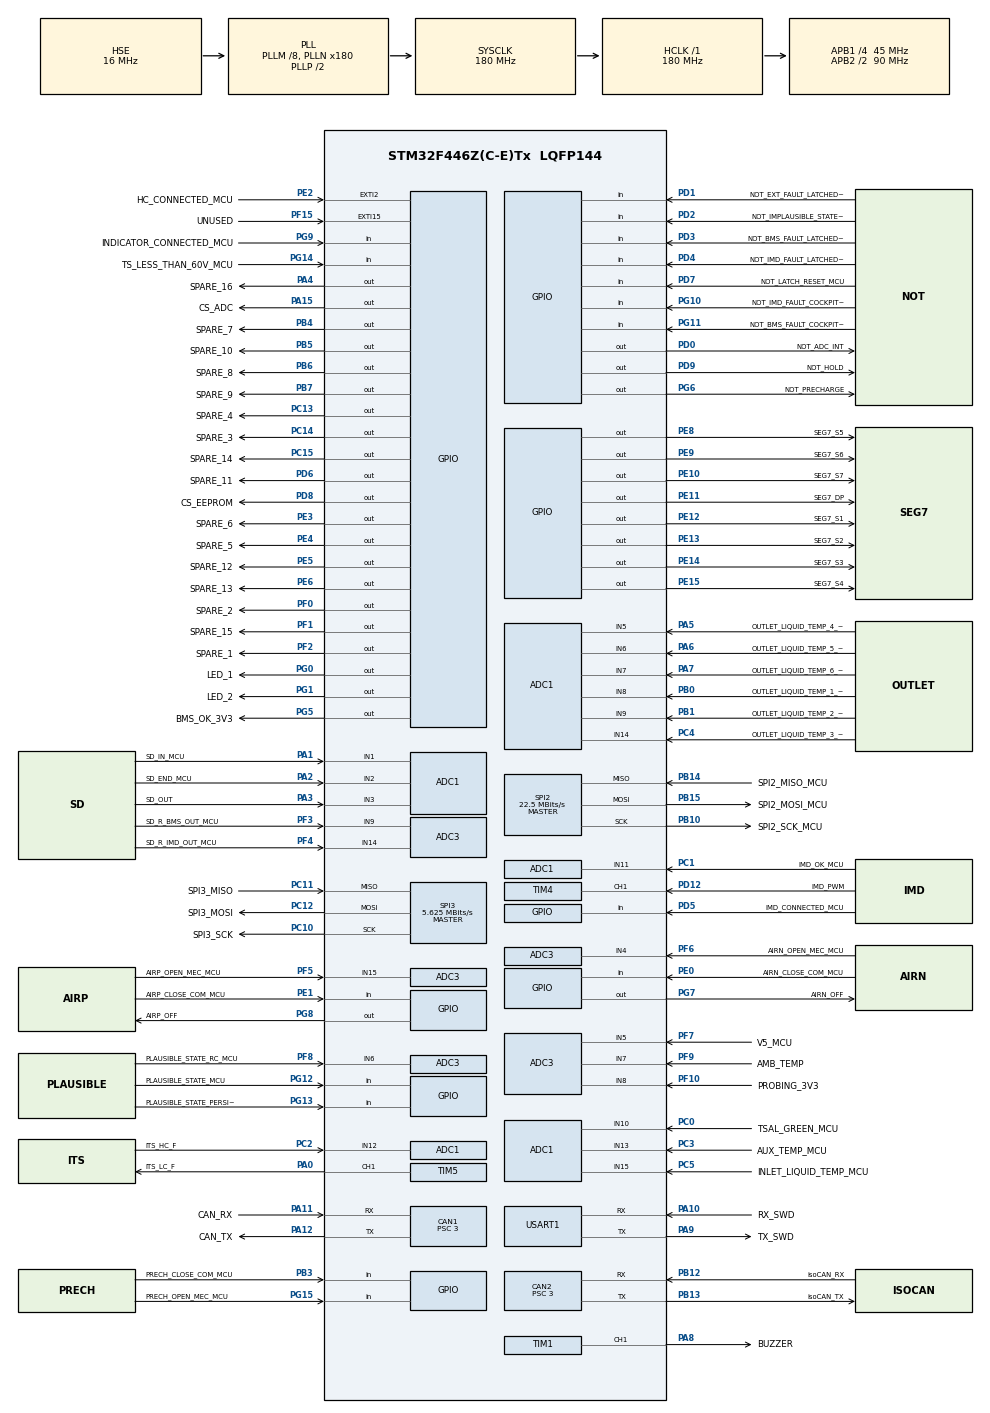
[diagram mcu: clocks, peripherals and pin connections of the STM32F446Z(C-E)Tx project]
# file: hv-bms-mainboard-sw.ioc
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ADC1.Channel-0\#ChannelRegularConversion=ADC_CHANNEL_15
ADC1.Channel-1\#ChannelRegularConversion=ADC_CHANNEL_1
ADC1.Channel-10\#ChannelRegularConversion=ADC_CHANNEL_11
ADC1.Channel-11\#ChannelRegularConversion=ADC_CHANNEL_12
ADC1.Channel-12\#ChannelRegularConversion=ADC_CHANNEL_13
ADC1.Channel-13\#ChannelRegularConversion=ADC_CHANNEL_14
ADC1.Channel-14\#ChannelRegularConversion=ADC_CHANNEL_15
ADC1.Channel-2\#ChannelRegularConversion=ADC_CHANNEL_2
ADC1.Channel-3\#ChannelRegularConversion=ADC_CHANNEL_3
ADC1.Channel-4\#ChannelRegularConversion=ADC_CHANNEL_5
ADC1.Channel-5\#ChannelRegularConversion=ADC_CHANNEL_6
ADC1.Channel-6\#ChannelRegularConversion=ADC_CHANNEL_7
ADC1.Channel-7\#ChannelRegularConversion=ADC_CHANNEL_8
ADC1.Channel-8\#ChannelRegularConversion=ADC_CHANNEL_9
ADC1.Channel-9\#ChannelRegularConversion=ADC_CHANNEL_10
ADC1.ClockPrescaler=ADC_CLOCK_SYNC_PCLK_DIV4
ADC1.DiscontinuousConvMode=DISABLE
ADC1.EOCSelection=ADC_EOC_SEQ_CONV
ADC1.NbrOfConversion=15
ADC1.NbrOfConversionFlag=1
ADC1.Rank-0\#ChannelRegularConversion=1
ADC1.Rank-1\#ChannelRegularConversion=2
ADC1.Rank-10\#ChannelRegularConversion=11
ADC1.Rank-11\#ChannelRegularConversion=12
ADC1.Rank-12\#ChannelRegularConversion=13
ADC1.Rank-13\#ChannelRegularConversion=14
ADC1.Rank-14\#ChannelRegularConversion=15
ADC1.Rank-2\#ChannelRegularConversion=3
ADC1.Rank-3\#ChannelRegularConversion=4
ADC1.Rank-4\#ChannelRegularConversion=5
ADC1.Rank-5\#ChannelRegularConversion=6
ADC1.Rank-6\#ChannelRegularConversion=7
ADC1.Rank-7\#ChannelRegularConversion=8
ADC1.Rank-8\#ChannelRegularConversion=9
ADC1.Rank-9\#ChannelRegularConversion=10
ADC1.SamplingTime-0\#ChannelRegularConversion=ADC_SAMPLETIME_15CYCLES
ADC1.SamplingTime-1\#ChannelRegularConversion=ADC_SAMPLETIME_15CYCLES
ADC1.SamplingTime-10\#ChannelRegularConversion=ADC_SAMPLETIME_15CYCLES
ADC1.SamplingTime-11\#ChannelRegularConversion=ADC_SAMPLETIME_15CYCLES
ADC1.SamplingTime-12\#ChannelRegularConversion=ADC_SAMPLETIME_15CYCLES
ADC1.SamplingTime-13\#ChannelRegularConversion=ADC_SAMPLETIME_15CYCLES
ADC1.SamplingTime-14\#ChannelRegularConversion=ADC_SAMPLETIME_15CYCLES
ADC1.SamplingTime-2\#ChannelRegularConversion=ADC_SAMPLETIME_15CYCLES
ADC1.SamplingTime-3\#ChannelRegularConversion=ADC_SAMPLETIME_15CYCLES
ADC1.SamplingTime-4\#ChannelRegularConversion=ADC_SAMPLETIME_15CYCLES
ADC1.SamplingTime-5\#ChannelRegularConversion=ADC_SAMPLETIME_15CYCLES
ADC1.SamplingTime-6\#ChannelRegularConversion=ADC_SAMPLETIME_15CYCLES
ADC1.SamplingTime-7\#ChannelRegularConversion=ADC_SAMPLETIME_15CYCLES
ADC1.SamplingTime-8\#ChannelRegularConversion=ADC_SAMPLETIME_15CYCLES
ADC1.SamplingTime-9\#ChannelRegularConversion=ADC_SAMPLETIME_15CYCLES
ADC1.master=1
ADC3.Channel-10\#ChannelRegularConversion=ADC_CHANNEL_8
ADC3.Channel-11\#ChannelRegularConversion=ADC_CHANNEL_9
ADC3.Channel-12\#ChannelRegularConversion=ADC_CHANNEL_14
ADC3.Channel-13\#ChannelRegularConversion=ADC_CHANNEL_15
ADC3.Channel-6\#ChannelRegularConversion=ADC_CHANNEL_4
ADC3.Channel-7\#ChannelRegularConversion=ADC_CHANNEL_5
ADC3.Channel-8\#ChannelRegularConversion=ADC_CHANNEL_6
ADC3.Channel-9\#ChannelRegularConversion=ADC_CHANNEL_7
ADC3.EOCSelection=ADC_EOC_SEQ_CONV
ADC3.NbrOfConversion=8
ADC3.NbrOfConversionFlag=1
ADC3.Rank-10\#ChannelRegularConversion=5
ADC3.Rank-11\#ChannelRegularConversion=6
ADC3.Rank-12\#ChannelRegularConversion=7
ADC3.Rank-13\#ChannelRegularConversion=8
ADC3.Rank-6\#ChannelRegularConversion=1
ADC3.Rank-7\#ChannelRegularConversion=2
ADC3.Rank-8\#ChannelRegularConversion=3
ADC3.Rank-9\#ChannelRegularConversion=4
ADC3.SamplingTime-10\#ChannelRegularConversion=ADC_SAMPLETIME_15CYCLES
ADC3.SamplingTime-11\#ChannelRegularConversion=ADC_SAMPLETIME_15CYCLES
ADC3.SamplingTime-12\#ChannelRegularConversion=ADC_SAMPLETIME_15CYCLES
ADC3.SamplingTime-13\#ChannelRegularConversion=ADC_SAMPLETIME_3CYCLES
ADC3.SamplingTime-6\#ChannelRegularConversion=ADC_SAMPLETIME_15CYCLES
ADC3.SamplingTime-7\#ChannelRegularConversion=ADC_SAMPLETIME_15CYCLES
ADC3.SamplingTime-8\#ChannelRegularConversion=ADC_SAMPLETIME_15CYCLES
ADC3.SamplingTime-9\#ChannelRegularConversion=ADC_SAMPLETIME_15CYCLES
ADC3.ScanConvMode=ENABLE
CAN1.ABOM=ENABLE
CAN1.BS1=CAN_BS1_12TQ
CAN1.BS2=CAN_BS2_2TQ
CAN1.CalculateBaudRate=1000000
CAN1.CalculateTimeBit=1000
CAN1.CalculateTimeQuantum=66.66666666666666
CAN1.NART=ENABLE
CAN1.Prescaler=3
CAN2.ABOM=ENABLE
CAN2.BS1=CAN_BS1_12TQ
CAN2.BS2=CAN_BS2_2TQ
CAN2.CalculateBaudRate=1000000
CAN2.CalculateTimeBit=1000
CAN2.CalculateTimeQuantum=66.66666666666666
CAN2.NART=ENABLE
CAN2.Prescaler=3
Dma.ADC1.0.Direction=DMA_PERIPH_TO_MEMORY
Dma.ADC1.0.FIFOMode=DMA_FIFOMODE_DISABLE
Dma.ADC1.0.Instance=DMA2_Stream0
Dma.ADC1.0.MemDataAlignment=DMA_MDATAALIGN_HALFWORD
Dma.ADC1.0.MemInc=DMA_MINC_ENABLE
Dma.ADC1.0.Mode=DMA_NORMAL
Dma.ADC1.0.PeriphDataAlignment=DMA_PDATAALIGN_HALFWORD
Dma.ADC1.0.PeriphInc=DMA_PINC_DISABLE
Dma.ADC1.0.Priority=DMA_PRIORITY_LOW
Dma.ADC3.1.Direction=DMA_PERIPH_TO_MEMORY
Dma.ADC3.1.FIFOMode=DMA_FIFOMODE_DISABLE
Dma.ADC3.1.Instance=DMA2_Stream1
Dma.ADC3.1.MemDataAlignment=DMA_MDATAALIGN_HALFWORD
Dma.ADC3.1.MemInc=DMA_MINC_ENABLE
Dma.ADC3.1.Mode=DMA_NORMAL
Dma.ADC3.1.PeriphDataAlignment=DMA_PDATAALIGN_HALFWORD
Dma.ADC3.1.PeriphInc=DMA_PINC_DISABLE
Dma.ADC3.1.Priority=DMA_PRIORITY_LOW
Dma.Request0=ADC1
Dma.Request1=ADC3
Dma.Request2=USART1_RX
Dma.Request3=USART1_TX
Dma.USART1_RX.2.Direction=DMA_PERIPH_TO_MEMORY
Dma.USART1_RX.2.FIFOMode=DMA_FIFOMODE_DISABLE
Dma.USART1_RX.2.Instance=DMA2_Stream2
Dma.USART1_RX.2.MemDataAlignment=DMA_MDATAALIGN_BYTE
Dma.USART1_RX.2.MemInc=DMA_MINC_ENABLE
Dma.USART1_RX.2.Mode=DMA_CIRCULAR
Dma.USART1_RX.2.PeriphDataAlignment=DMA_PDATAALIGN_BYTE
Dma.USART1_RX.2.PeriphInc=DMA_PINC_DISABLE
Dma.USART1_RX.2.Priority=DMA_PRIORITY_LOW
Dma.USART1_TX.3.Direction=DMA_MEMORY_TO_PERIPH
Dma.USART1_TX.3.FIFOMode=DMA_FIFOMODE_DISABLE
Dma.USART1_TX.3.Instance=DMA2_Stream7
Dma.USART1_TX.3.MemDataAlignment=DMA_MDATAALIGN_BYTE
Dma.USART1_TX.3.MemInc=DMA_MINC_ENABLE
Dma.USART1_TX.3.Mode=DMA_NORMAL
Dma.USART1_TX.3.PeriphDataAlignment=DMA_PDATAALIGN_BYTE
Dma.USART1_TX.3.PeriphInc=DMA_PINC_DISABLE
Dma.USART1_TX.3.Priority=DMA_PRIORITY_LOW
Mcu.Family=STM32F4
Mcu.Name=STM32F446Z(C-E)Tx
Mcu.Package=LQFP144
NVIC.CAN1_RX0_IRQn=true\:0\:0\:false\:false\:true\:true\:true\:true
NVIC.CAN1_RX1_IRQn=true\:0\:0\:false\:false\:true\:true\:true\:true
NVIC.CAN1_SCE_IRQn=true\:0\:0\:false\:false\:true\:true\:true\:true
NVIC.CAN2_RX0_IRQn=true\:0\:0\:false\:false\:true\:true\:true\:true
NVIC.CAN2_RX1_IRQn=true\:0\:0\:false\:false\:true\:true\:true\:true
NVIC.CAN2_SCE_IRQn=true\:0\:0\:false\:false\:true\:true\:true\:true
NVIC.DMA2_Stream0_IRQn=true\:0\:0\:false\:false\:true\:false\:true\:true
NVIC.DMA2_Stream1_IRQn=true\:0\:0\:false\:false\:true\:false\:true\:true
NVIC.DMA2_Stream2_IRQn=true\:0\:0\:false\:false\:true\:false\:true\:true
NVIC.DMA2_Stream7_IRQn=true\:0\:0\:false\:false\:true\:false\:true\:true
NVIC.EXTI2_IRQn=true\:0\:0\:false\:false\:true\:true\:true\:true
NVIC.PriorityGroup=NVIC_PRIORITYGROUP_4
NVIC.TIM4_IRQn=true\:0\:0\:false\:false\:true\:true\:true\:true
NVIC.TIM6_DAC_IRQn=true\:0\:0\:false\:false\:true\:true\:true\:true
NVIC.TIM7_IRQn=true\:0\:0\:false\:false\:true\:true\:true\:true
NVIC.USART1_IRQn=true\:0\:0\:false\:false\:true\:true\:true\:true
PA0-WKUP.GPIO_Label=ITS_LC_F
PA0-WKUP.Signal=S_TIM5_CH1
PA1.GPIO_Label=SD_IN_MCU
PA1.Signal=ADCx_IN1
PA10.GPIO_Label=RX_SWD
PA10.Mode=Asynchronous
PA10.Signal=USART1_RX
PA11.GPIO_Label=CAN_RX
PA11.Mode=CAN_Activate
PA11.Signal=CAN1_RX
PA12.GPIO_Label=CAN_TX
PA12.Mode=CAN_Activate
PA12.Signal=CAN1_TX
PA13.GPIO_Label=SWDIO
PA13.Mode=Serial_Wire
PA13.Signal=SYS_JTMS-SWDIO
PA14.GPIO_Label=SWCLK
PA14.Mode=Serial_Wire
PA14.Signal=SYS_JTCK-SWCLK
PA15.GPIO_Label=CS_ADC
PA15.Signal=GPIO_Output
PA2.GPIO_Label=SD_END_MCU
PA2.Signal=ADCx_IN2
PA3.GPIO_Label=SD_OUT
PA3.Signal=ADCx_IN3
PA4.GPIO_Label=SPARE_16
PA4.Signal=GPIO_Output
PA5.GPIO_Label=OUTLET_LIQUID_TEMP_4_MCU
PA5.Signal=ADCx_IN5
PA6.GPIO_Label=OUTLET_LIQUID_TEMP_5_MCU
PA6.Signal=ADCx_IN6
PA7.GPIO_Label=OUTLET_LIQUID_TEMP_6_MCU
PA7.Signal=ADCx_IN7
PA8.GPIO_Label=BUZZER
PA8.Signal=S_TIM1_CH1
PA9.GPIO_Label=TX_SWD
PA9.Mode=Asynchronous
PA9.Signal=USART1_TX
PB0.GPIO_Label=OUTLET_LIQUID_TEMP_1_MCU
PB0.Signal=ADCx_IN8
PB1.GPIO_Label=OUTLET_LIQUID_TEMP_2_MCU
PB1.Signal=ADCx_IN9
PB10.GPIO_Label=SPI2_SCK_MCU
PB10.Mode=Full_Duplex_Master
PB10.Signal=SPI2_SCK
PB12.GPIO_Label=isoCAN_RX
PB12.Mode=CAN_Activate
PB12.Signal=CAN2_RX
PB13.GPIO_Label=isoCAN_TX
PB13.Mode=CAN_Activate
PB13.Signal=CAN2_TX
PB14.GPIO_Label=SPI2_MISO_MCU
PB14.Mode=Full_Duplex_Master
PB14.Signal=SPI2_MISO
PB15.GPIO_Label=SPI2_MOSI_MCU
PB15.Mode=Full_Duplex_Master
PB15.Signal=SPI2_MOSI
PB3.GPIO_Label=PRECH_CLOSE_COM_MCU
PB3.Signal=GPIO_Input
PB4.GPIO_Label=SPARE_7
PB4.Signal=GPIO_Output
PB5.GPIO_Label=SPARE_10
PB5.Signal=GPIO_Output
PB6.GPIO_Label=SPARE_8
PB6.Signal=GPIO_Output
PB7.GPIO_Label=SPARE_9
PB7.Signal=GPIO_Output
PC0.GPIO_Label=TSAL_GREEN_MCU
PC0.Signal=ADCx_IN10
PC1.GPIO_Label=IMD_OK_MCU
PC1.Signal=ADCx_IN11
PC10.GPIO_Label=SPI3_SCK
PC10.Mode=Full_Duplex_Master
PC10.Signal=SPI3_SCK
PC11.GPIO_Label=SPI3_MISO
PC11.Mode=Full_Duplex_Master
PC11.Signal=SPI3_MISO
PC12.GPIO_Label=SPI3_MOSI
PC12.Mode=Full_Duplex_Master
PC12.Signal=SPI3_MOSI
PC13.GPIO_Label=SPARE_4
PC13.Signal=GPIO_Output
PC14-OSC32_IN.GPIO_Label=SPARE_3
PC14-OSC32_IN.Signal=GPIO_Output
PC15-OSC32_OUT.GPIO_Label=SPARE_14
PC15-OSC32_OUT.Signal=GPIO_Output
PC2.GPIO_Label=ITS_HC_F
PC2.Signal=ADCx_IN12
PC3.GPIO_Label=AUX_TEMP_MCU
PC3.Signal=ADCx_IN13
PC4.GPIO_Label=OUTLET_LIQUID_TEMP_3_MCU
PC4.Signal=ADCx_IN14
PC5.GPIO_Label=INLET_LIQUID_TEMP_MCU
PC5.Signal=ADCx_IN15
PD0.GPIO_Label=NOT_ADC_INT
PD0.Signal=GPIO_Output
PD1.GPIO_Label=NOT_EXT_FAULT_LATCHED_MCU
PD1.Signal=GPIO_Input
PD12.GPIO_Label=IMD_PWM
PD12.Signal=S_TIM4_CH1
PD2.GPIO_Label=NOT_IMPLAUSIBLE_STATE_LATCHED_MCU
PD2.Signal=GPIO_Input
PD3.GPIO_Label=NOT_BMS_FAULT_LATCHED_MCU
PD3.Signal=GPIO_Input
PD4.GPIO_Label=NOT_IMD_FAULT_LATCHED_MCU
PD4.Signal=GPIO_Input
PD5.GPIO_Label=IMD_CONNECTED_MCU
PD5.Signal=GPIO_Input
PD6.GPIO_Label=SPARE_11
PD6.Signal=GPIO_Output
PD7.GPIO_Label=NOT_LATCH_RESET_MCU
PD7.Signal=GPIO_Input
PD8.GPIO_Label=CS_EEPROM
PD8.Signal=GPIO_Output
PD9.GPIO_Label=NOT_HOLD
PD9.Signal=GPIO_Output
PE0.GPIO_Label=AIRN_CLOSE_COM_MCU
PE0.GPIO_PuPd=GPIO_NOPULL
PE0.Signal=GPIO_Input
PE1.GPIO_Label=AIRP_CLOSE_COM_MCU
PE1.Signal=GPIO_Input
PE10.GPIO_Label=SEG7_S7
PE10.Signal=GPIO_Output
PE11.GPIO_Label=SEG7_DP
PE11.Signal=GPIO_Output
PE12.GPIO_Label=SEG7_S1
PE12.Signal=GPIO_Output
PE13.GPIO_Label=SEG7_S2
PE13.Signal=GPIO_Output
PE14.GPIO_Label=SEG7_S3
PE14.Signal=GPIO_Output
PE15.GPIO_Label=SEG7_S4
PE15.Signal=GPIO_Output
PE2.GPIO_Label=HC_CONNECTED_MCU
PE2.GPIO_ModeDefaultEXTI=GPIO_MODE_IT_RISING_FALLING
PE2.Signal=GPXTI2
PE3.GPIO_Label=SPARE_6
PE3.Signal=GPIO_Output
PE4.GPIO_Label=SPARE_5
PE4.Signal=GPIO_Output
PE5.GPIO_Label=SPARE_12
PE5.Signal=GPIO_Output
PE6.GPIO_Label=SPARE_13
PE6.Signal=GPIO_Output
PE8.GPIO_Label=SEG7_S5
PE8.Signal=GPIO_Output
PE9.GPIO_Label=SEG7_S6
PE9.Signal=GPIO_Output
PF0.GPIO_Label=SPARE_2
PF0.Signal=GPIO_Output
PF1.GPIO_Label=SPARE_15
PF1.Signal=GPIO_Output
PF10.GPIO_Label=PROBING_3V3
PF10.Mode=IN8
PF10.Signal=ADC3_IN8
PF15.GPIO_Label=UNUSED
PF15.GPIO_PuPd=GPIO_PULLDOWN
PF15.Signal=GPXTI15
PF2.GPIO_Label=SPARE_1
PF2.Signal=GPIO_Output
PF3.GPIO_Label=SD_R_BMS_OUT_MCU
PF3.Mode=IN9
PF3.Signal=ADC3_IN9
PF4.GPIO_Label=SD_R_IMD_OUT_MCU
PF4.Mode=IN14
PF4.Signal=ADC3_IN14
PF5.GPIO_Label=AIRP_OPEN_MEC_MCU
PF5.Mode=IN15
PF5.Signal=ADC3_IN15
PF6.GPIO_Label=AIRN_OPEN_MEC_MCU
PF6.Mode=IN4
PF6.Signal=ADC3_IN4
PF7.GPIO_Label=V5_MCU
PF7.Mode=IN5
PF7.Signal=ADC3_IN5
PF8.GPIO_Label=PLAUSIBLE_STATE_RC_MCU
PF8.Mode=IN6
PF8.Signal=ADC3_IN6
PF9.GPIO_Label=AMB_TEMP
PF9.Mode=IN7
PF9.Signal=ADC3_IN7
PG0.GPIO_Label=LED_1
PG0.Signal=GPIO_Output
PG1.GPIO_Label=LED_2
PG1.Signal=GPIO_Output
PG10.GPIO_Label=NOT_IMD_FAULT_COCKPIT_LED_MCU
PG10.Signal=GPIO_Input
PG11.GPIO_Label=NOT_BMS_FAULT_COCKPIT_LED_MCU
PG11.Signal=GPIO_Input
PG12.GPIO_Label=PLAUSIBLE_STATE_MCU
PG12.GPIO_PuPd=GPIO_NOPULL
PG12.Signal=GPIO_Input
PG13.GPIO_Label=PLAUSIBLE_STATE_PERSISTED_MCU
PG13.Signal=GPIO_Input
PG14.GPIO_Label=TS_LESS_THAN_60V_MCU
PG14.Signal=GPIO_Input
PG15.GPIO_Label=PRECH_OPEN_MEC_MCU
PG15.Signal=GPIO_Input
PG5.GPIO_Label=BMS_OK_3V3
PG5.Signal=GPIO_Output
PG6.GPIO_Label=NOT_PRECHARGE
PG6.Signal=GPIO_Output
PG7.GPIO_Label=AIRN_OFF
PG7.Signal=GPIO_Output
PG8.GPIO_Label=AIRP_OFF
PG8.Signal=GPIO_Output
PG9.GPIO_Label=INDICATOR_CONNECTED_MCU
PG9.Signal=GPIO_Input
PH0-OSC_IN.GPIO_Label=OSC_IN
PH0-OSC_IN.Mode=HSE-External-Oscillator
PH0-OSC_IN.Signal=RCC_OSC_IN
PH1-OSC_OUT.GPIO_Label=OSC_OUT
PH1-OSC_OUT.Mode=HSE-External-Oscillator
PH1-OSC_OUT.Signal=RCC_OSC_OUT
ProjectManager.HeapSize=0x200
ProjectManager.StackSize=0x400
ProjectManager.TargetToolchain=Makefile
RCC.AHBFreq_Value=180000000
RCC.APB1CLKDivider=RCC_HCLK_DIV4
RCC.APB1Freq_Value=45000000
RCC.APB1TimFreq_Value=90000000
RCC.APB2CLKDivider=RCC_HCLK_DIV2
RCC.APB2Freq_Value=90000000
RCC.APB2TimFreq_Value=180000000
RCC.CortexFreq_Value=180000000
RCC.HCLKFreq_Value=180000000
RCC.HSE_VALUE=16000000
RCC.PLLM=8
RCC.PLLN=180
RCC.PLLSourceVirtual=RCC_PLLSOURCE_HSE
RCC.SYSCLKFreq_VALUE=180000000
RCC.SYSCLKSource=RCC_SYSCLKSOURCE_PLLCLK
RCC.USBFreq_Value=180000000
RCC.VCOOutputFreq_Value=360000000
SH.ADCx_IN1.0=ADC1_IN1,IN1
SH.ADCx_IN10.0=ADC1_IN10,IN10
SH.ADCx_IN11.0=ADC1_IN11,IN11
SH.ADCx_IN12.0=ADC1_IN12,IN12
SH.ADCx_IN13.0=ADC1_IN13,IN13
SH.ADCx_IN14.0=ADC1_IN14,IN14
SH.ADCx_IN15.0=ADC1_IN15,IN15
SH.ADCx_IN2.0=ADC1_IN2,IN2
SH.ADCx_IN3.0=ADC1_IN3,IN3
SH.ADCx_IN5.0=ADC1_IN5,IN5
SH.ADCx_IN6.0=ADC1_IN6,IN6
SH.ADCx_IN7.0=ADC1_IN7,IN7
SH.ADCx_IN8.0=ADC1_IN8,IN8
SH.ADCx_IN9.0=ADC1_IN9,IN9
SH.S_TIM1_CH1.0=TIM1_CH1,PWM Generation1 CH1
SH.S_TIM4_CH1.0=TIM4_CH1,PWM_Input_1
SH.S_TIM5_CH1.0=TIM5_CH1,PWM Generation1 CH1
SPI2.BaudRatePrescaler=SPI_BAUDRATEPRESCALER_2
SPI2.CalculateBaudRate=22.5 MBits/s
SPI2.Direction=SPI_DIRECTION_2LINES
SPI2.Mode=SPI_MODE_MASTER
SPI2.VirtualType=VM_MASTER
SPI3.BaudRatePrescaler=SPI_BAUDRATEPRESCALER_8
SPI3.CLKPhase=SPI_PHASE_1EDGE
SPI3.CalculateBaudRate=5.625 MBits/s
SPI3.Direction=SPI_DIRECTION_2LINES
SPI3.Mode=SPI_MODE_MASTER
SPI3.VirtualType=VM_MASTER
TIM1.Channel-PWM\ Generation1\ CH1=TIM_CHANNEL_1
TIM4.Channel-PWM\ Generation1\ CH1=TIM_CHANNEL_1
TIM4.Prescaler=89
TIM5.AutoReloadPreload=TIM_AUTORELOAD_PRELOAD_ENABLE
TIM5.Channel-PWM\ Generation1\ CH1=TIM_CHANNEL_1
TIM5.Period=1000
TIM5.Prescaler=8999
TIM6.Period=999
TIM6.Prescaler=89
USART1.VirtualMode=VM_ASYNC
VP_ADC1_Vref_Input.Mode=IN-Vrefint
VP_TIM1_VS_ClockSourceINT.Mode=Internal
VP_TIM2_VS_ClockSourceINT.Mode=Internal
VP_TIM4_VS_ClockSourceINT.Mode=Internal
VP_TIM6_VS_ClockSourceINT.Mode=Enable_Timer
VP_TIM7_VS_ClockSourceINT.Mode=Enable_Timer
board=custom

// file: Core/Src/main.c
/* USER CODE BEGIN Header */
/**
  ******************************************************************************
  * @file           : main.c
  * @brief          : Main program body
  ******************************************************************************
  * @attention
  *
  * Copyright (c) 2024 STMicroelectronics.
  * All rights reserved.
  *
  * This software is licensed under terms that can be found in the LICENSE file
  * in the root directory of this software component.
  * If no LICENSE file comes with this software, it is provided AS-IS.
  *
  ******************************************************************************
  */
/* USER CODE END Header */
#include "main.h"
#include "adc.h"
#include "can.h"
#include "dma.h"
#include "spi.h"
#include "tim.h"
#include "usart.h"
#include "gpio.h"

/* USER CODE BEGIN Includes */

#include "stm32f4xx_it.h"

#include "eagletrt-api.h"

#include "mainboard-tasks-api.h"
#include "mainboard-watchdogs-api.h"
#include "pcu-api.h"
#include "post-api.h"
#include "post.h"
#include "serializer-tasks-api.h"
#include "mainboard-logger-api.h"
/* USER CODE END Includes */

void SystemClock_Config(void);
/* USER CODE BEGIN PFP */

void system_reset(void);

/* USER CODE END PFP */

int main(void) {

    /* MCU Configuration--------------------------------------------------------*/

    /* Reset of all peripherals, Initializes the Flash interface and the Systick. */
    HAL_Init();

    /* Configure the system clock */
    SystemClock_Config();

    /* Initialize all configured peripherals */
    MX_GPIO_Init();
    MX_DMA_Init();
    MX_ADC1_Init();
    MX_CAN1_Init();
    MX_CAN2_Init();
    MX_ADC3_Init();
    MX_SPI2_Init();
    MX_TIM1_Init();
    MX_TIM2_Init();
    MX_TIM4_Init();
    MX_USART1_UART_Init();
    MX_SPI3_Init();
    MX_TIM6_Init();
    MX_TIM7_Init();
    MX_TIM5_Init();
    /* USER CODE BEGIN 2 */

    // First so that every following initialization can be logged
    const struct MainboardLoggerInitData logger_data = {
        .write = usart_send,
        .read = usart_receive,
        .free_space = usart_get_tx_free_space,
        .get_tick = HAL_GetTick,
        .reset = system_reset,
        .verbosity = LOGGER_ENABLE_ALL,
    };
    if (mainboard_logger_api_init(&logger_data) != LOGGER_RC_OK) {
        Error_Handler();
    }

    MAINBOARD_LOGGER_INFO("Logger initialized, running POST");

    // Configure and start CAN given if the handcart is connected or not
    // The handcart charger uses 250K baud rate, the vehicle 1M
    can_configure_and_start_primary(gpio_read_hc_connected());

    /*
     * Open the relays and pull the AMS OK pin high as soon as possible,
     * the GPIO initialization leaves them low (relays closed, AMS active)
     */
    if (pcu_api_init(gpio_pcu_set_state, system_reset) != PCU_RC_OK) {
        Error_Handler();
    }

    const struct PostInitData init_data = {
        .send_primary = can_send_primary,
        .send_bms = can_send_bms,
        .tx_ready_primary = can_tx_ready_primary,
        .tx_ready_bms = can_tx_ready_bms,
        .status_primary = can_get_status_primary,
        .status_bms = can_get_status_bms,
        .cs_enter = it_cs_enter,
        .cs_exit = it_cs_exit,
        .led_set = gpio_led_set_state,
        .led_toggle = gpio_led_toggle_state,
        .display_set = gpio_display_segment_set_state,
        .display_toggle = gpio_display_segment_toggle_state,
        .get_tick = HAL_GetTick,
        .sensing = {
                    .gpio_read = gpio_sensing_read,
                    .adc_start = adc_sensing_start,
                    .imd_start = tim_start_pwm_imd,
                    .spi_send = spi_send,
                    .spi_send_receive = spi_send_receive,
                    },
    };

    EAGLETRT_API_UNUSED(post_api_run(&init_data));

    MAINBOARD_LOGGER_INFO("POST ran, starting main application, press h for the console commands");

    /* USER CODE END 2 */

    /* Infinite loop */
    while (1) {

        /* USER CODE BEGIN 3 */
        EAGLETRT_API_UNUSED(serializer_tasks_api_routine());
        EAGLETRT_API_UNUSED(mainboard_tasks_api_routine());

        // Outside of the tasks so that the timeouts do not depend on the scheduler, an error latches the watchdogs fault
        EAGLETRT_API_UNUSED(mainboard_watchdogs_api_routine());
    }
    /* USER CODE END 3 */
}

void SystemClock_Config(void) {
    RCC_OscInitTypeDef RCC_OscInitStruct = { 0 };
    RCC_ClkInitTypeDef RCC_ClkInitStruct = { 0 };

    /** Configure the main internal regulator output voltage
  */
    __HAL_RCC_PWR_CLK_ENABLE();
    __HAL_PWR_VOLTAGESCALING_CONFIG(PWR_REGULATOR_VOLTAGE_SCALE1);

    /** Initializes the RCC Oscillators according to the specified parameters
  * in the RCC_OscInitTypeDef structure.
  */
    RCC_OscInitStruct.OscillatorType = RCC_OSCILLATORTYPE_HSE;
    RCC_OscInitStruct.HSEState = RCC_HSE_ON;
    RCC_OscInitStruct.PLL.PLLState = RCC_PLL_ON;
    RCC_OscInitStruct.PLL.PLLSource = RCC_PLLSOURCE_HSE;
    RCC_OscInitStruct.PLL.PLLM = 8;
    RCC_OscInitStruct.PLL.PLLN = 180;
    RCC_OscInitStruct.PLL.PLLP = RCC_PLLP_DIV2;
    RCC_OscInitStruct.PLL.PLLQ = 2;
    RCC_OscInitStruct.PLL.PLLR = 2;
    if (HAL_RCC_OscConfig(&RCC_OscInitStruct) != HAL_OK) {
        Error_Handler();
    }

    /** Activate the Over-Drive mode
  */
    if (HAL_PWREx_EnableOverDrive() != HAL_OK) {
        Error_Handler();
    }

    /** Initializes the CPU, AHB and APB buses clocks
  */
    RCC_ClkInitStruct.ClockType = RCC_CLOCKTYPE_HCLK | RCC_CLOCKTYPE_SYSCLK | RCC_CLOCKTYPE_PCLK1 | RCC_CLOCKTYPE_PCLK2;
    RCC_ClkInitStruct.SYSCLKSource = RCC_SYSCLKSOURCE_PLLCLK;
    RCC_ClkInitStruct.AHBCLKDivider = RCC_SYSCLK_DIV1;
    RCC_ClkInitStruct.APB1CLKDivider = RCC_HCLK_DIV4;
    RCC_ClkInitStruct.APB2CLKDivider = RCC_HCLK_DIV2;

    if (HAL_RCC_ClockConfig(&RCC_ClkInitStruct, FLASH_LATENCY_5) != HAL_OK) {
        Error_Handler();
    }
}

/* USER CODE BEGIN 4 */

void system_reset(void) {
    HAL_NVIC_SystemReset();
}

/* USER CODE END 4 */

void Error_Handler(void) {
    __disable_irq();
    while (1) {
    }
}
